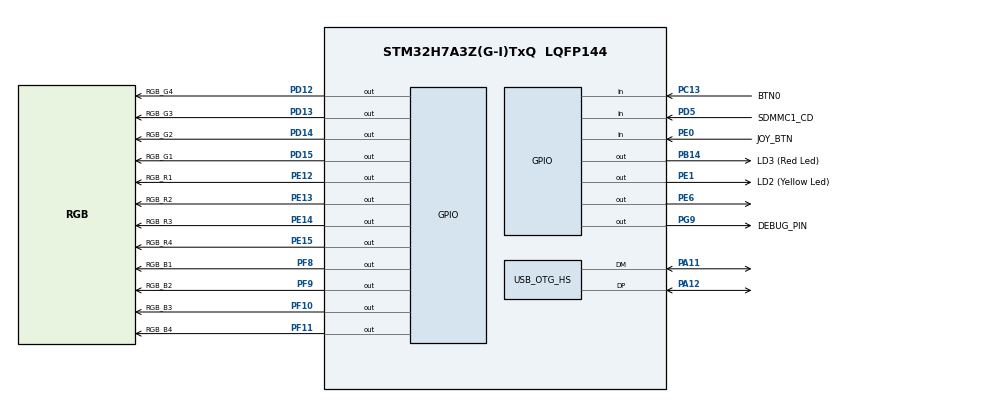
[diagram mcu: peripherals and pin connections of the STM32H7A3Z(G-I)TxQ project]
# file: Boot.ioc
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CORTEX_M7.AccessPermission-Cortex_Memory_Protection_Unit_Region0_Settings=MPU_REGION_FULL_ACCESS
CORTEX_M7.CPU_DCache=Disabled
CORTEX_M7.CPU_ICache=Enabled
CORTEX_M7.Enable-Cortex_Memory_Protection_Unit_Region0_Settings=MPU_REGION_ENABLE
CORTEX_M7.MPU_Control=__NULL
CORTEX_M7.Size-Cortex_Memory_Protection_Unit_Region0_Settings=MPU_REGION_SIZE_32KB
CORTEX_M7.default_mode_Activation=1
Mcu.Family=STM32H7
Mcu.Name=STM32H7A3Z(G-I)TxQ
Mcu.Package=LQFP144
Mcu.UserConstants=ere,ere
NVIC.PriorityGroup=NVIC_PRIORITYGROUP_4
PA11.Mode=Device_Only_FS
PA11.Signal=USB_OTG_HS_DM
PA12.Mode=Device_Only_FS
PA12.Signal=USB_OTG_HS_DP
PA15.Signal=SPI1_NSS
PB14.GPIO_Label=LD3 (Red Led)
PB14.Signal=GPIO_Output
PB3.Signal=SPI1_SCK
PC13.GPIO_Label=BTN0
PC13.GPIO_PuPd=GPIO_NOPULL
PC13.Signal=GPIO_Input
PC8.GPIO_PuPd=GPIO_PULLDOWN
PC8.Signal=SDMMC1_D0
PD12.GPIO_Label=RGB_G4
PD12.Signal=GPIO_Output
PD13.GPIO_Label=RGB_G3
PD13.Signal=GPIO_Output
PD14.GPIO_Label=RGB_G2
PD14.Signal=GPIO_Output
PD15.GPIO_Label=RGB_G1
PD15.Signal=GPIO_Output
PD5.GPIO_Label=SDMMC1_CD
PD5.Signal=GPIO_Input
PD8.GPIO_Label=STLINK_RX
PD8.Signal=USART3_TX
PD9.GPIO_Label=STLINK_TX
PD9.Signal=USART3_RX
PE0.GPIO_Label=JOY_BTN
PE0.GPIO_PuPd=GPIO_PULLUP
PE0.Signal=GPIO_Input
PE1.GPIO_Label=LD2 (Yellow Led)
PE1.Signal=GPIO_Output
PE12.GPIO_Label=RGB_R1
PE12.Signal=GPIO_Output
PE13.GPIO_Label=RGB_R2
PE13.Signal=GPIO_Output
PE14.GPIO_Label=RGB_R3
PE14.Signal=GPIO_Output
PE15.GPIO_Label=RGB_R4
PE15.Signal=GPIO_Output
PE6.Signal=GPIO_Output
PF10.GPIO_Label=RGB_B3
PF10.Signal=GPIO_Output
PF11.GPIO_Label=RGB_B4
PF11.Signal=GPIO_Output
PF8.GPIO_Label=RGB_B1
PF8.Signal=GPIO_Output
PF9.GPIO_Label=RGB_B2
PF9.Signal=GPIO_Output
PG9.GPIO_Label=DEBUG_PIN
PG9.GPIO_Speed=GPIO_SPEED_FREQ_HIGH
PG9.Signal=GPIO_Output
ProjectManager.HeapSize=0x200
ProjectManager.StackSize=0x400
ProjectManager.TargetToolchain=STM32CubeIDE
RCC.ADCFreq_Value=64000000
RCC.APB1Freq_Value=140000000
RCC.APB2Freq_Value=140000000
RCC.APB3Freq_Value=140000000
RCC.APB4Freq_Value=140000000
RCC.CDPPRE=RCC_APB3_DIV2
RCC.CDPPRE1=RCC_APB1_DIV2
RCC.CDPPRE2=RCC_APB2_DIV2
RCC.CortexFreq_Value=280000000
RCC.DIVM1=4
RCC.DIVM2=4
RCC.DIVM3=1
RCC.DIVN1=35
RCC.DIVN2=8
RCC.DIVN3=55
RCC.DIVQ1=7
RCC.DIVQ3=16
RCC.DIVR2=1
RCC.HCLKFreq_Value=280000000
RCC.HSE_VALUE=8000000
RCC.PLL2FRACN=0
RCC.PLLFRACN=0
RCC.SPI123CLockSelection=RCC_SPI123CLKSOURCE_CLKP
RCC.SRDPPRE=RCC_APB4_DIV2
RCC.SYSCLKFreq_VALUE=280000000
RCC.SYSCLKSource=RCC_SYSCLKSOURCE_PLLCLK
RCC.SupplySource=PWR_DIRECT_SMPS_SUPPLY
RCC.USBCLockSelection=RCC_USBCLKSOURCE_HSI48
RCC.USBFreq_Value=48000000
USB_OTG_HS.VirtualMode-Device_Only_FS=Device_Only_FS
board=NUCLEO-H7A3ZI-Q

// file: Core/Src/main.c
/* USER CODE BEGIN Header */
/**
  ******************************************************************************
  * @file           : main.c
  * @brief          : Main program body
  ******************************************************************************
  * @attention
  *
  * <h2><center>&copy; Copyright (c) 2020 STMicroelectronics.
  * All rights reserved.</center></h2>
  *
  * This software component is licensed by ST under BSD 3-Clause license,
  * the "License"; You may not use this file except in compliance with the
  * License. You may obtain a copy of the License at:
  *                        opensource.org/licenses/BSD-3-Clause
  *
  ******************************************************************************
  */
/* USER CODE END Header */
#include "main.h"

/* USER CODE BEGIN Includes */
#include "app.h"
/* USER CODE END Includes */

PCD_HandleTypeDef hpcd_USB_OTG_HS;

void SystemClock_Config(void);
static void MX_GPIO_Init(void);

int main(void)
{

  /* Enable I-Cache---------------------------------------------------------*/
 // SCB_EnableICache();

  /* MCU Configuration--------------------------------------------------------*/

  /* Reset of all peripherals, Initializes the Flash interface and the Systick. */
  HAL_Init();

  /* Configure the system clock */
  SystemClock_Config();

  /* Initialize all configured peripherals */
  MX_GPIO_Init();
  /* USER CODE BEGIN 2 */
  /* Initialize the bootloader application. */
  AppInit();
  /* USER CODE END 2 */

  /* Infinite loop */
  /* USER CODE BEGIN WHILE */
  while (1)
  {
    /* Run the bootloader application. */
    AppTask();
    /* USER CODE END WHILE */

  }
}

void SystemClock_Config(void)
{

  /*AXI clock gating */
  RCC->CKGAENR = 0xFFFFFFFF;

  LL_FLASH_SetLatency(LL_FLASH_LATENCY_7);
  while(LL_FLASH_GetLatency()!= LL_FLASH_LATENCY_7)
  {
  }
  LL_PWR_ConfigSupply(LL_PWR_DIRECT_SMPS_SUPPLY);
  LL_PWR_SetRegulVoltageScaling(LL_PWR_REGU_VOLTAGE_SCALE0);
  LL_RCC_HSI_Enable();

   /* Wait till HSI is ready */
  while(LL_RCC_HSI_IsReady() != 1)
  {

  }
  LL_RCC_HSI_SetCalibTrimming(32);
  LL_RCC_HSI_SetDivider(LL_RCC_HSI_DIV1);
  LL_RCC_HSI48_Enable();

   /* Wait till HSI48 is ready */
  while(LL_RCC_HSI48_IsReady() != 1)
  {

  }
  LL_RCC_PLL_SetSource(LL_RCC_PLLSOURCE_HSI);
  LL_RCC_PLL1P_Enable();
  LL_RCC_PLL1_SetVCOInputRange(LL_RCC_PLLINPUTRANGE_8_16);
  LL_RCC_PLL1_SetVCOOutputRange(LL_RCC_PLLVCORANGE_WIDE);
  LL_RCC_PLL1_SetM(4);
  LL_RCC_PLL1_SetN(35);
  LL_RCC_PLL1_SetP(2);
  LL_RCC_PLL1_SetQ(7);
  LL_RCC_PLL1_SetR(2);
  LL_RCC_PLL1_Enable();

   /* Wait till PLL is ready */
  while(LL_RCC_PLL1_IsReady() != 1)
  {
  }

   /* Intermediate AHB prescaler 2 when target frequency clock is higher than 80 MHz */
   LL_RCC_SetAHBPrescaler(LL_RCC_AHB_DIV_2);

  LL_RCC_SetSysClkSource(LL_RCC_SYS_CLKSOURCE_PLL1);

   /* Wait till System clock is ready */
  while(LL_RCC_GetSysClkSource() != LL_RCC_SYS_CLKSOURCE_STATUS_PLL1)
  {

  }
  LL_RCC_SetAHBPrescaler(LL_RCC_AHB_DIV_1);
  LL_RCC_SetAPB1Prescaler(LL_RCC_APB1_DIV_2);
  LL_RCC_SetAPB2Prescaler(LL_RCC_APB2_DIV_2);
  LL_RCC_SetAPB3Prescaler(LL_RCC_APB3_DIV_2);
  LL_RCC_SetAPB4Prescaler(LL_RCC_APB4_DIV_2);
  LL_SetSystemCoreClock(280000000);

   /* Update the time base */
  if (HAL_InitTick (TICK_INT_PRIORITY) != HAL_OK)
  {
    Error_Handler();
  }
}

static void MX_GPIO_Init(void)
{
  LL_GPIO_InitTypeDef GPIO_InitStruct = {0};

  /* GPIO Ports Clock Enable */
  LL_AHB4_GRP1_EnableClock(LL_AHB4_GRP1_PERIPH_GPIOE);
  LL_AHB4_GRP1_EnableClock(LL_AHB4_GRP1_PERIPH_GPIOC);
  LL_AHB4_GRP1_EnableClock(LL_AHB4_GRP1_PERIPH_GPIOF);
  LL_AHB4_GRP1_EnableClock(LL_AHB4_GRP1_PERIPH_GPIOB);
  LL_AHB4_GRP1_EnableClock(LL_AHB4_GRP1_PERIPH_GPIOD);
  LL_AHB4_GRP1_EnableClock(LL_AHB4_GRP1_PERIPH_GPIOA);
  LL_AHB4_GRP1_EnableClock(LL_AHB4_GRP1_PERIPH_GPIOG);

  /**/
  LL_GPIO_ResetOutputPin(GPIOE, LL_GPIO_PIN_6|RGB_R1_Pin|RGB_R2_Pin|RGB_R3_Pin
                          |RGB_R4_Pin|LD2_Pin);

  /**/
  LL_GPIO_ResetOutputPin(GPIOF, RGB_B1_Pin|RGB_B2_Pin|RGB_B3_Pin|RGB_B4_Pin);

  /**/
  LL_GPIO_ResetOutputPin(LD3_GPIO_Port, LD3_Pin);

  /**/
  LL_GPIO_ResetOutputPin(GPIOD, RGB_G4_Pin|RGB_G3_Pin|RGB_G2_Pin|RGB_G1_Pin);

  /**/
  LL_GPIO_ResetOutputPin(DEBUG_PIN_GPIO_Port, DEBUG_PIN_Pin);

  /**/
  GPIO_InitStruct.Pin = LL_GPIO_PIN_6|RGB_R1_Pin|RGB_R2_Pin|RGB_R3_Pin
                          |RGB_R4_Pin|LD2_Pin;
  GPIO_InitStruct.Mode = LL_GPIO_MODE_OUTPUT;
  GPIO_InitStruct.Speed = LL_GPIO_SPEED_FREQ_LOW;
  GPIO_InitStruct.OutputType = LL_GPIO_OUTPUT_PUSHPULL;
  GPIO_InitStruct.Pull = LL_GPIO_PULL_NO;
  LL_GPIO_Init(GPIOE, &GPIO_InitStruct);

  /**/
  GPIO_InitStruct.Pin = BTN0_Pin;
  GPIO_InitStruct.Mode = LL_GPIO_MODE_INPUT;
  GPIO_InitStruct.Pull = LL_GPIO_PULL_NO;
  LL_GPIO_Init(BTN0_GPIO_Port, &GPIO_InitStruct);

  /**/
  GPIO_InitStruct.Pin = RGB_B1_Pin|RGB_B2_Pin|RGB_B3_Pin|RGB_B4_Pin;
  GPIO_InitStruct.Mode = LL_GPIO_MODE_OUTPUT;
  GPIO_InitStruct.Speed = LL_GPIO_SPEED_FREQ_LOW;
  GPIO_InitStruct.OutputType = LL_GPIO_OUTPUT_PUSHPULL;
  GPIO_InitStruct.Pull = LL_GPIO_PULL_NO;
  LL_GPIO_Init(GPIOF, &GPIO_InitStruct);

  /**/
  GPIO_InitStruct.Pin = LD3_Pin;
  GPIO_InitStruct.Mode = LL_GPIO_MODE_OUTPUT;
  GPIO_InitStruct.Speed = LL_GPIO_SPEED_FREQ_LOW;
  GPIO_InitStruct.OutputType = LL_GPIO_OUTPUT_PUSHPULL;
  GPIO_InitStruct.Pull = LL_GPIO_PULL_NO;
  LL_GPIO_Init(LD3_GPIO_Port, &GPIO_InitStruct);

  /**/
  GPIO_InitStruct.Pin = STLINK_RX_Pin|STLINK_TX_Pin;
  GPIO_InitStruct.Mode = LL_GPIO_MODE_ALTERNATE;
  GPIO_InitStruct.Speed = LL_GPIO_SPEED_FREQ_LOW;
  GPIO_InitStruct.OutputType = LL_GPIO_OUTPUT_PUSHPULL;
  GPIO_InitStruct.Pull = LL_GPIO_PULL_NO;
  GPIO_InitStruct.Alternate = LL_GPIO_AF_7;
  LL_GPIO_Init(GPIOD, &GPIO_InitStruct);

  /**/
  GPIO_InitStruct.Pin = RGB_G4_Pin|RGB_G3_Pin|RGB_G2_Pin|RGB_G1_Pin;
  GPIO_InitStruct.Mode = LL_GPIO_MODE_OUTPUT;
  GPIO_InitStruct.Speed = LL_GPIO_SPEED_FREQ_LOW;
  GPIO_InitStruct.OutputType = LL_GPIO_OUTPUT_PUSHPULL;
  GPIO_InitStruct.Pull = LL_GPIO_PULL_NO;
  LL_GPIO_Init(GPIOD, &GPIO_InitStruct);

  /**/
  GPIO_InitStruct.Pin = LL_GPIO_PIN_8;
  GPIO_InitStruct.Mode = LL_GPIO_MODE_ALTERNATE;
  GPIO_InitStruct.Speed = LL_GPIO_SPEED_FREQ_VERY_HIGH;
  GPIO_InitStruct.OutputType = LL_GPIO_OUTPUT_PUSHPULL;
  GPIO_InitStruct.Pull = LL_GPIO_PULL_DOWN;
  GPIO_InitStruct.Alternate = LL_GPIO_AF_12;
  LL_GPIO_Init(GPIOC, &GPIO_InitStruct);

  /**/
  GPIO_InitStruct.Pin = LL_GPIO_PIN_15;
  GPIO_InitStruct.Mode = LL_GPIO_MODE_ALTERNATE;
  GPIO_InitStruct.Speed = LL_GPIO_SPEED_FREQ_LOW;
  GPIO_InitStruct.OutputType = LL_GPIO_OUTPUT_PUSHPULL;
  GPIO_InitStruct.Pull = LL_GPIO_PULL_NO;
  GPIO_InitStruct.Alternate = LL_GPIO_AF_5;
  LL_GPIO_Init(GPIOA, &GPIO_InitStruct);

  /**/
  GPIO_InitStruct.Pin = SDMMC1_CD_Pin;
  GPIO_InitStruct.Mode = LL_GPIO_MODE_INPUT;
  GPIO_InitStruct.Pull = LL_GPIO_PULL_NO;
  LL_GPIO_Init(SDMMC1_CD_GPIO_Port, &GPIO_InitStruct);

  /**/
  GPIO_InitStruct.Pin = DEBUG_PIN_Pin;
  GPIO_InitStruct.Mode = LL_GPIO_MODE_OUTPUT;
  GPIO_InitStruct.Speed = LL_GPIO_SPEED_FREQ_HIGH;
  GPIO_InitStruct.OutputType = LL_GPIO_OUTPUT_PUSHPULL;
  GPIO_InitStruct.Pull = LL_GPIO_PULL_NO;
  LL_GPIO_Init(DEBUG_PIN_GPIO_Port, &GPIO_InitStruct);

  /**/
  GPIO_InitStruct.Pin = LL_GPIO_PIN_3;
  GPIO_InitStruct.Mode = LL_GPIO_MODE_ALTERNATE;
  GPIO_InitStruct.Speed = LL_GPIO_SPEED_FREQ_LOW;
  GPIO_InitStruct.OutputType = LL_GPIO_OUTPUT_PUSHPULL;
  GPIO_InitStruct.Pull = LL_GPIO_PULL_NO;
  GPIO_InitStruct.Alternate = LL_GPIO_AF_5;
  LL_GPIO_Init(GPIOB, &GPIO_InitStruct);

  /**/
  GPIO_InitStruct.Pin = JOY_BTN_Pin;
  GPIO_InitStruct.Mode = LL_GPIO_MODE_INPUT;
  GPIO_InitStruct.Pull = LL_GPIO_PULL_UP;
  LL_GPIO_Init(JOY_BTN_GPIO_Port, &GPIO_InitStruct);

}

void Error_Handler(void)
{
}
